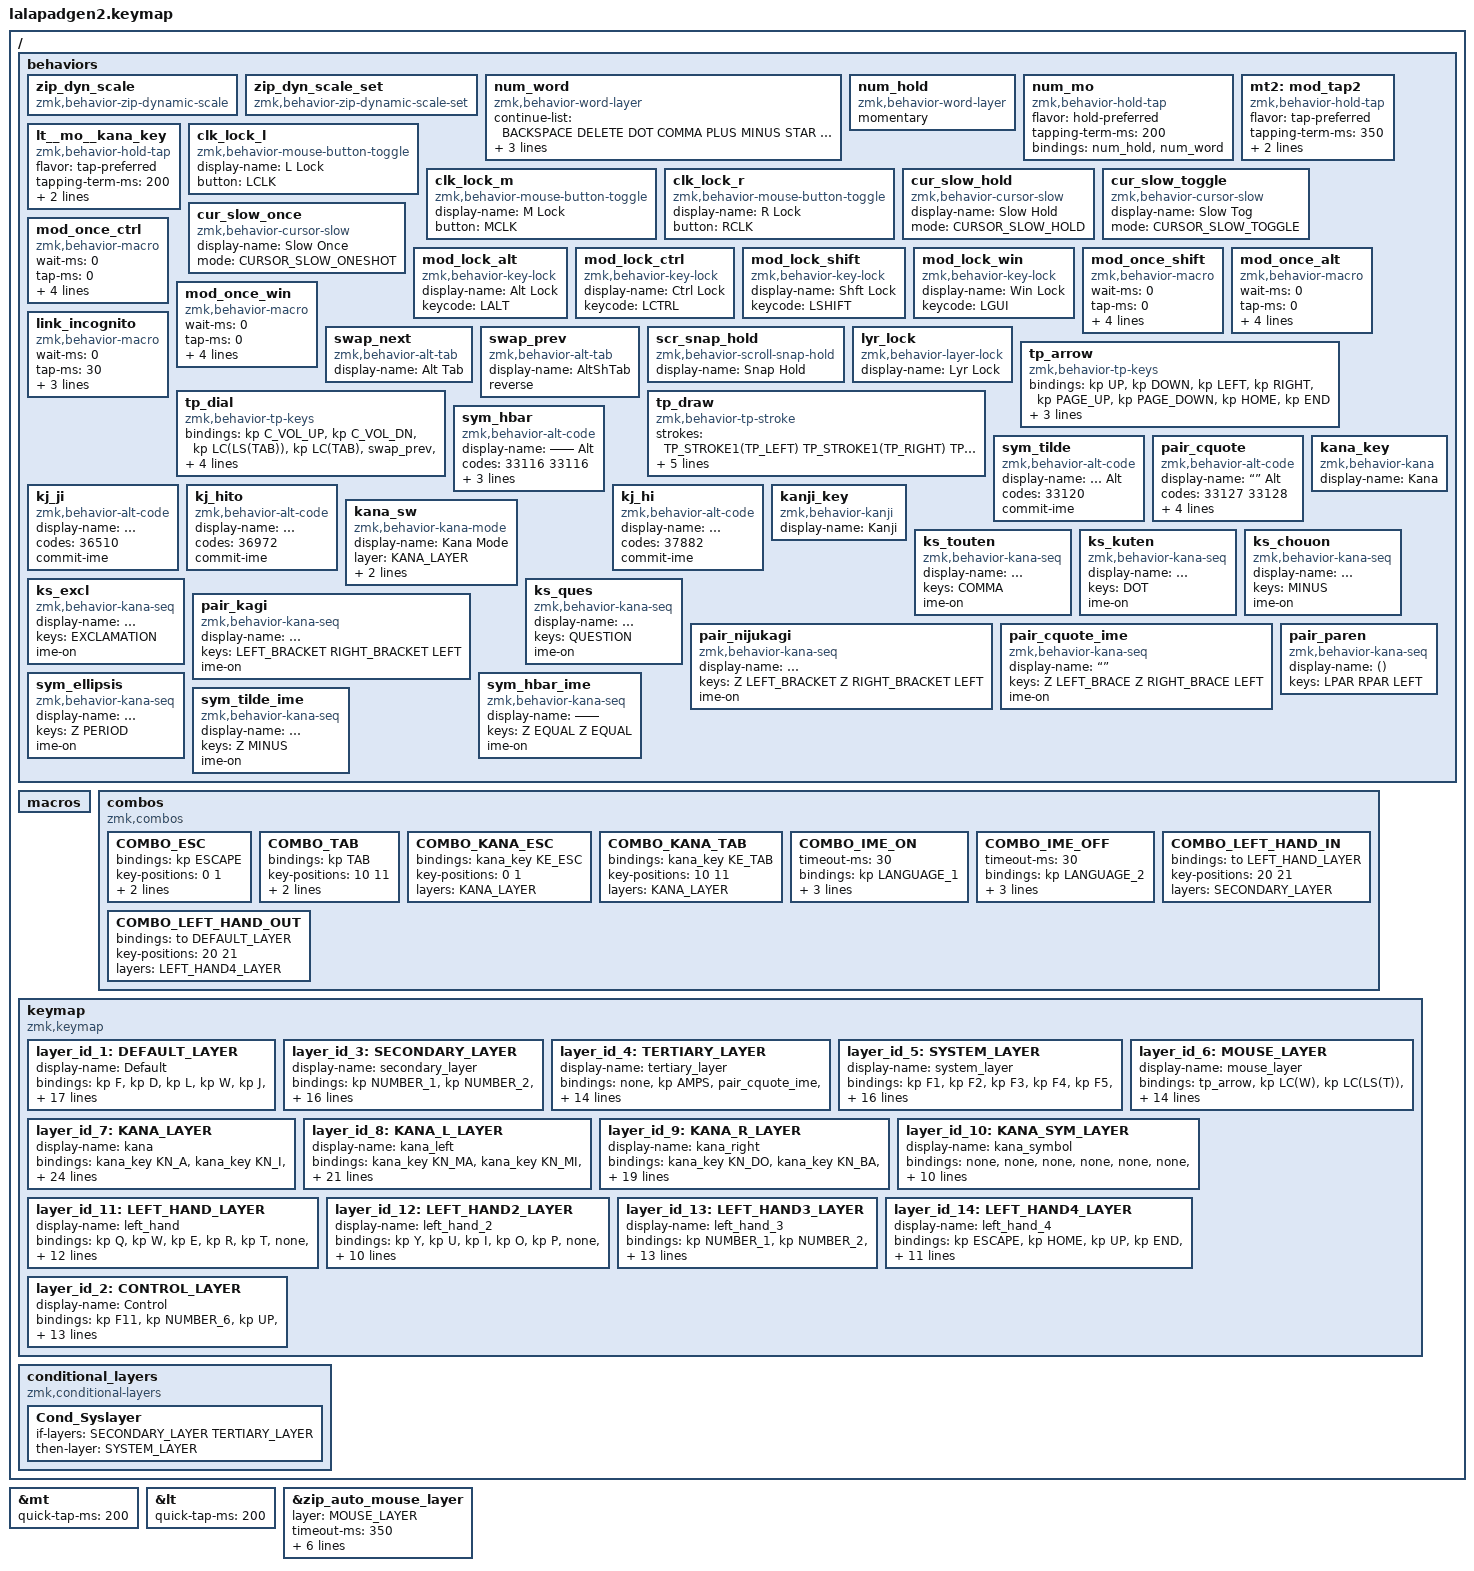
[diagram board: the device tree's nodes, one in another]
#include <input/processors.dtsi>
#include <dt-bindings/zmk/zip_dynamic_scale.h>
#include <behaviors.dtsi>
#include <dt-bindings/zmk/bt.h>
#include <dt-bindings/zmk/keys.h>
#include <dt-bindings/zmk/outputs.h>
#include <dt-bindings/zmk/pointing.h>
#include <behaviors/kana.dtsi>
#include <dt-bindings/kana/kanji.h>
#include <behaviors/mouse_button_toggle.dtsi>
#include <dt-bindings/lalapad/cursor_slow.h>
#include <dt-bindings/lalapad/tp_keys.h>
#include <dt-bindings/lalapad/tp_positions.h>

#define DEFAULT_LAYER   0
#define CONTROL_LAYER   13
#define SECONDARY_LAYER 1
#define TERTIARY_LAYER  2
#define SYSTEM_LAYER    3
#define MOUSE_LAYER     4
#define KANA_LAYER      5
#define KANA_L_LAYER    6
#define KANA_R_LAYER    7
#define KANA_SYM_LAYER  8
#define LEFT_HAND_LAYER  9
#define LEFT_HAND2_LAYER 10
#define LEFT_HAND3_LAYER 11
#define LEFT_HAND4_LAYER 12

// &mt・&lt: 短く押してから 200ms 以内にもう一度押し続けると、長押しにせずタップを押し続ける（Space の連続入力など）。
// &mt は今どこにも置いていない（エディタで置いたときの既定）
&mt { quick-tap-ms = <200>; };

&lt { quick-tap-ms = <200>; };

// オートマウスレイヤー（lalapadgen2.dtsi）のうち、マウスレイヤーに結びつく設定
// - layer: トラックパッドを操作したときに有効にするレイヤー。timeout-ms: 指とキーを離してから解除するまでの時間
// - excluded-layers: 数字・記号レイヤーの間は、トラックパッドを操作してもマウスレイヤーにしない
// - excluded-positions: マウスレイヤーで &trans でも、押しても解除せず、押している間は時間切れにしない位置
//   （トラックパッドのクリック・ジェスチャー 52〜67。POS_TP_* は dt-bindings/lalapad/tp_positions.h。離してから数え直す）
// - passive-positions: マウスレイヤーに割り当てがあっても、押しても解除も延長もしない位置（親指の段の 30〜41 のうち、
//   33・34 以外。マウスレイヤーで &trans の位置（36〜38）は、ほかのキーと同じく押すと解除する）
&zip_auto_mouse_layer {
    layer = <MOUSE_LAYER>;
    timeout-ms = <350>;
    excluded-layers = <SECONDARY_LAYER TERTIARY_LAYER>;
    excluded-positions = <
        POS_TP_LCLK_L POS_TP_RCLK_L POS_TP_MCLK_L POS_TP_LCLK_R POS_TP_RCLK_R POS_TP_MCLK_R
        POS_TP_SWIPE_RIGHT_L POS_TP_SWIPE_LEFT_L POS_TP_SWIPE_UP_L POS_TP_SWIPE_DOWN_L POS_TP_PINCH_L
        POS_TP_SWIPE_RIGHT_R POS_TP_SWIPE_LEFT_R POS_TP_SWIPE_UP_R POS_TP_SWIPE_DOWN_R POS_TP_PINCH_R
    >;
    passive-positions = <30 31 32 35 36 37 38 39 40 41>;
};


/ {
    behaviors {
        zip_dyn_scale: zip_dyn_scale {
            compatible = "zmk,behavior-zip-dynamic-scale";
            #binding-cells = <2>;
        };

        zip_dyn_scale_set: zip_dyn_scale_set {
            compatible = "zmk,behavior-zip-dynamic-scale-set";
            #binding-cells = <2>;
        };

        // Num Word（自作モジュール lalapad/ の zmk,behavior-word-layer）: 数字レイヤーを、数字と continue-list のキー
        // （Backspace・Delete・. , + - * / =）を押している間だけ続け、ほかのキーを押すと自動で戻す。Shift などの修飾キーでは
        // 戻さない（ignore-modifiers）。ほかの操作（20＋21 のコンボの &to など）で数字レイヤーが解除されたら、こちらも終わる。
        // 記号レイヤー（38）を押したら終える（exit-layers）: 数字レイヤーと記号レイヤーが同時に有効になると
        // システムレイヤー（bootloader・BT_CLR など）になるため。Num Word の間に 38 を押すと、記号レイヤーになる。
        // 使い方: &num_word SECONDARY_LAYER
        num_word: num_word {
            compatible = "zmk,behavior-word-layer";
            #binding-cells = <1>;
            continue-list = <BACKSPACE DELETE DOT COMMA PLUS MINUS STAR FSLH EQUAL>;
            ignore-numbers;
            ignore-modifiers;
            exit-layers = <TERTIARY_LAYER>;
        };

        // 33 の長押し: 押している間だけ数字レイヤー（&mo と同じ）。Num Word の間に押したら、Num Word を引き継ぐ
        // （ほかのキーや 38 を押しても数字レイヤーのまま。33 と 38 でシステムレイヤーになる）。
        // 使い方: &num_hold SECONDARY_LAYER
        num_hold: num_hold {
            compatible = "zmk,behavior-word-layer";
            #binding-cells = <1>;
            momentary;
        };

        // 33: タップで Num Word（数字レイヤーを、数字を打っている間だけ続ける）、長押しで今までどおり押している間だけ
        // 数字レイヤー（num_hold）。長押しの間にほかのキーを押したら、すぐに長押しとして扱う（hold-preferred）。
        // 使い方: &num_mo SECONDARY_LAYER SECONDARY_LAYER
        num_mo: num_mo {
            compatible = "zmk,behavior-hold-tap";
            #binding-cells = <2>;
            flavor = "hold-preferred";
            tapping-term-ms = <200>;
            bindings = <&num_hold>, <&num_word>;
        };

        mt2: mod_tap2 {
            compatible = "zmk,behavior-hold-tap";
            #binding-cells = <2>;
            flavor = "tap-preferred";
            tapping-term-ms = <350>;
            quick-tap-ms = <200>;
            // require-prior-idle-ms（以前は 125）は外した。直前の打鍵から 125ms 以内に押すと、長押ししても
            // Shift にならず、押したままのタップとして rrrr と連続入力になったため。戻すときは次の行を足す
            //   require-prior-idle-ms = <125>;
            bindings = <&kp>, <&kp>;
        };
        lt__mo__kana_key: lt__mo__kana_key {
            compatible = "zmk,behavior-hold-tap";
            #binding-cells = <2>;
            flavor = "tap-preferred";
            tapping-term-ms = <200>;
            quick-tap-ms = <200>;
            bindings = <&mo>, <&kana_key>;
        };

        // ===== カスタムキー（エディタで使いたいレイヤーに割り当てる） =====
        // 名前の頭で種類を分けている（clk_: クリック、cur_: カーソル、mod_: 修飾キー、swap_: ウィンドウの切り替え、scr_: スクロール、lyr_: レイヤー、num_: Num Word、link_: Chrome のリンク、tp_: トラックパッドでキー操作、ks_: かなと一緒に打つ記号、pair_: カッコ、sym_: 記号、kj_: 漢字 1 文字、kana_: かな）。
        // display-name は ZMK Studio の一覧とキーの上に出る名前（キーの上は 9 文字まで）。

        // --- clk_: クリック押しっぱなし（もう一度押す、または同じボタンのクリックで解除） ---
        // 左クリック押しっぱなし（旧 D.LCK）
        clk_lock_l: clk_lock_l {
            compatible = "zmk,behavior-mouse-button-toggle";
            display-name = "L Lock";
            #binding-cells = <0>;
            button = <LCLK>;
        };
        // 中クリック押しっぱなし（旧 D.MID）
        clk_lock_m: clk_lock_m {
            compatible = "zmk,behavior-mouse-button-toggle";
            display-name = "M Lock";
            #binding-cells = <0>;
            button = <MCLK>;
        };
        // 右クリック押しっぱなし（旧 D.RCK）
        clk_lock_r: clk_lock_r {
            compatible = "zmk,behavior-mouse-button-toggle";
            display-name = "R Lock";
            #binding-cells = <0>;
            button = <RCLK>;
        };

        // --- cur_: カーソル低速（1/3） ---
        // 押している間、カーソル低速（旧 SLOW）
        cur_slow_hold: cur_slow_hold {
            compatible = "zmk,behavior-cursor-slow";
            display-name = "Slow Hold";
            #binding-cells = <0>;
            mode = <CURSOR_SLOW_HOLD>;
        };
        // 押すたびにカーソル低速のオン・オフ（旧 T.SLO）
        cur_slow_toggle: cur_slow_toggle {
            compatible = "zmk,behavior-cursor-slow";
            display-name = "Slow Tog";
            #binding-cells = <0>;
            mode = <CURSOR_SLOW_TOGGLE>;
        };
        // 次のキーを押すまでカーソル低速（旧 O.SLO）
        cur_slow_once: cur_slow_once {
            compatible = "zmk,behavior-cursor-slow";
            display-name = "Slow Once";
            #binding-cells = <0>;
            mode = <CURSOR_SLOW_ONESHOT>;
        };

        // --- mod_: 修飾キー押しっぱなし（もう一度押すと解除） ---
        // Left Alt 押しっぱなし（旧 A.LCK）
        mod_lock_alt: mod_lock_alt {
            compatible = "zmk,behavior-key-lock";
            display-name = "Alt Lock";
            #binding-cells = <0>;
            keycode = <LALT>;
        };
        // Left Ctrl 押しっぱなし（旧 C.LCK）
        mod_lock_ctrl: mod_lock_ctrl {
            compatible = "zmk,behavior-key-lock";
            display-name = "Ctrl Lock";
            #binding-cells = <0>;
            keycode = <LCTRL>;
        };
        // Left Shift 押しっぱなし（旧 S.LCK）
        mod_lock_shift: mod_lock_shift {
            compatible = "zmk,behavior-key-lock";
            display-name = "Shft Lock";
            #binding-cells = <0>;
            keycode = <LSHIFT>;
        };
        // Left GUI（Win）押しっぱなし（旧 W.LCK）
        mod_lock_win: mod_lock_win {
            compatible = "zmk,behavior-key-lock";
            display-name = "Win Lock";
            #binding-cells = <0>;
            keycode = <LGUI>;
        };

        // --- mod_: 修飾キーを次の1キーだけにかける（ZMK 標準の &sk。押してから離し、次のキーを押すとそのキーと一緒に送られる。
        // 押したまま別のキーを押せば、ふつうの修飾キーとして働く） ---
        // &sk は引数でキーを受け取るので、名前付きのキーにするためマクロで包む（押したとき &sk を押し、離したとき離す）。
        // Left Ctrl を次の1キーだけ
        mod_once_ctrl: mod_once_ctrl {
            compatible = "zmk,behavior-macro";
            #binding-cells = <0>;
            wait-ms = <0>;
            tap-ms = <0>;
            bindings
                = <&macro_press &sk LCTRL>
                , <&macro_pause_for_release>
                , <&macro_release &sk LCTRL>
                ;
            display-name = "Ctrl Once";
        };
        // Left Shift を次の1キーだけ
        mod_once_shift: mod_once_shift {
            compatible = "zmk,behavior-macro";
            #binding-cells = <0>;
            wait-ms = <0>;
            tap-ms = <0>;
            bindings
                = <&macro_press &sk LSHIFT>
                , <&macro_pause_for_release>
                , <&macro_release &sk LSHIFT>
                ;
            display-name = "Shft Once";
        };
        // Left Alt を次の1キーだけ
        mod_once_alt: mod_once_alt {
            compatible = "zmk,behavior-macro";
            #binding-cells = <0>;
            wait-ms = <0>;
            tap-ms = <0>;
            bindings
                = <&macro_press &sk LALT>
                , <&macro_pause_for_release>
                , <&macro_release &sk LALT>
                ;
            display-name = "Alt Once";
        };
        // Left GUI（Win）を次の1キーだけ
        mod_once_win: mod_once_win {
            compatible = "zmk,behavior-macro";
            #binding-cells = <0>;
            wait-ms = <0>;
            tap-ms = <0>;
            bindings
                = <&macro_press &sk LGUI>
                , <&macro_pause_for_release>
                , <&macro_release &sk LGUI>
                ;
            display-name = "Win Once";
        };

        // --- swap_: ウィンドウの切り替え（Alt+Tab。自作モジュール lalapad/ の zmk,behavior-alt-tab） ---
        // 最初に押したときに Alt を押したままにして、押すたびに Tab（swap_prev は Shift+Tab）を送る。
        // 押し始めたときのレイヤーを離す（&mo のキーを離す）か、ほかのキー（キーコードを送るもの。クリックやレイヤーのキーは除く）を押すと
        // Alt を離して、選んだウィンドウに切り替わる。
        // swap_next と swap_prev は Alt を共有するので、どちらから押し始めても、途中で入れ替えてもよい
        swap_next: swap_next {
            compatible = "zmk,behavior-alt-tab";
            display-name = "Alt Tab";
            #binding-cells = <0>;
        };
        swap_prev: swap_prev {
            compatible = "zmk,behavior-alt-tab";
            display-name = "AltShTab";
            #binding-cells = <0>;
            reverse;
        };

        // --- scr_: スクロール ---
        // 押している間だけ、トラックパッドの2本指スクロールを縦か横のどちらかにそろえる（スクロールスナップ）。
        // レイヤーは使わない。実際の処理は lalapadgen2.dtsi の &zip_scroll_snap_gate_R / _L
        scr_snap_hold: scr_snap_hold {
            compatible = "zmk,behavior-scroll-snap-hold";
            display-name = "Snap Hold";
            #binding-cells = <0>;
        };

        // --- lyr_: レイヤー ---
        // レイヤーを固定する（Layer Lock。自作モジュール lalapad/ の zmk,behavior-layer-lock）。押すと、このキーを置いたレイヤーを
        // 固定する（&mo のキーを離しても、オートマウスレイヤーの時間切れでも切れない。マウスレイヤーでは、&trans のキーを
        // 押しても切れず、そのキーは下のレイヤーのキーとして入力される）。もう一度押すと固定をやめて、そのレイヤーを解除する
        // （オートマウスレイヤーなら、ふだんどおり手を離してから時間を数え直す）。Default と system_layer（数字＋記号で
        // 有効になるレイヤー）以外のどのレイヤーにも置ける。かなのレイヤーの固定は、かなモードを抜けるとやめる
        lyr_lock: lyr_lock {
            compatible = "zmk,behavior-layer-lock";
            display-name = "Lyr Lock";
            #binding-cells = <0>;
        };

        // --- link_: Chrome のリンク ---
        // カーソルを合わせたリンクを、シークレットウィンドウで開く。右クリックでメニューを出し、
        // メニューの「シークレット ウィンドウでリンクを開く」のアクセスキー G を押す（メニューが出るのを 200ms 待つ）
        link_incognito: link_incognito {
            compatible = "zmk,behavior-macro";
            #binding-cells = <0>;
            wait-ms = <0>;
            tap-ms = <30>;
            bindings
                = <&macro_wait_time 200>
                , <&mkp RCLK>
                , <&macro_wait_time 0>
                , <&kp G>
                ;
            display-name = "Incognito";
        };

        // --- tp_: トラックパッドをキー操作に変える（自作モジュール lalapad/ の zmk,behavior-tp-keys・zmk,behavior-tp-stroke） ---
        // 押している間だけ、トラックパッドの動きを、カーソル・スクロールの代わりにキーの入力に変える
        // （押している間のタップ・ジェスチャーは捨てる）。実際の処理は lalapadgen2.dtsi のリスナーに入れた &zip_tp_keys。
        // 直下の bindings はどのレイヤーでも使う既定。レイヤーごとに変えるときは、子ノード（表）に layers（使うレイヤー）と
        // bindings を書き足す（このキーを押したときに有効なレイヤーを上から見て、表のあるレイヤーの表を使う。表の &trans は
        // 下のレイヤーの表、最後に既定を見る）。左右のトラックパッドで変えるときは left-bindings・right-bindings に書く。
        // 例: num { layers = <SECONDARY_LAYER>; bindings = <...>; };
        // tp-keys の bindings は 8 つ: 1 本指を上・下・左・右へ動かしたとき、2 本指を上・下・左・右へ動かしたとき
        // （2 本指も指を動かした向き。スクロールの向きではない）。4 つとも &trans にした側は、変えずにカーソル（スクロール）のまま。
        // 動き始めの向きで縦か横かを決め、指が触れ直す・離れるか、このキーを押す・離すまで変えない。
        // *-step は 1 回送るのに必要な動きの量（トラックパッドの生の値。速度の設定には影響されない）。
        // 矢印: 1 本指で ←→↑↓、2 本指で上下が PgUp・PgDn、左右が Home・End
        tp_arrow: tp_arrow {
            compatible = "zmk,behavior-tp-keys";
            #binding-cells = <0>;
            bindings
                = <&kp UP>, <&kp DOWN>, <&kp LEFT>, <&kp RIGHT>
                , <&kp PAGE_UP>, <&kp PAGE_DOWN>, <&kp HOME>, <&kp END>
                ;
            cursor-step = <150>;
            scroll-step = <300>;
            display-name = "TP Arrow";
        };
        // ダイヤル: 1 本指で上下が音量、左右がタブ（Ctrl+Shift+Tab・Ctrl+Tab）。
        // 2 本指で上下がウィンドウの切り替え（指を上へ swap_prev・下へ swap_next。このキーを押したレイヤーが切れるか
        // （マウスレイヤーなら、キーとトラックパッドから手を離して 350ms 後）、ほかのキーを押すと、選んだウィンドウに
        // 切り替わる）、左右が仮想デスクトップ（Ctrl+Win+←・→）
        tp_dial: tp_dial {
            compatible = "zmk,behavior-tp-keys";
            #binding-cells = <0>;
            bindings
                = <&kp C_VOL_UP>, <&kp C_VOL_DN>, <&kp LC(LS(TAB))>, <&kp LC(TAB)>
                , <&swap_prev>, <&swap_next>, <&kp LC(LG(LEFT))>, <&kp LC(LG(RIGHT))>
                ;
            cursor-step = <300>;
            scroll-step = <300>;
            display-name = "TP Dial";
        };
        // 一筆書き: 押したまま 1 本指で線を描き、指（またはこのキー）を離すと、描いた向きの並びに合うものを送る。
        // strokes（向きの並び）は全レイヤー共通。bindings は strokes と同じ数・同じ順番（レイヤーごと・左右ごとの書き方は上の tp-keys と同じ）。
        // ← 戻る、→ 進む、↑ 新しいタブ、↓ 再読み込み、↓→ タブを閉じる、↓← 閉じたタブを開き直す、
        // ↑← 前のタブ、↑→ 次のタブ、→↓ シークレットウィンドウ
        tp_draw: tp_draw {
            compatible = "zmk,behavior-tp-stroke";
            #binding-cells = <0>;
            strokes = <
                TP_STROKE1(TP_LEFT)
                TP_STROKE1(TP_RIGHT)
                TP_STROKE1(TP_UP)
                TP_STROKE1(TP_DOWN)
                TP_STROKE2(TP_DOWN, TP_RIGHT)
                TP_STROKE2(TP_DOWN, TP_LEFT)
                TP_STROKE2(TP_UP, TP_LEFT)
                TP_STROKE2(TP_UP, TP_RIGHT)
                TP_STROKE2(TP_RIGHT, TP_DOWN)
                >;
            bindings
                = <&kp LA(LEFT)>
                , <&kp LA(RIGHT)>
                , <&kp LC(T)>
                , <&kp F5>
                , <&kp LC(W)>
                , <&kp LC(LS(T))>
                , <&kp LC(LS(TAB))>
                , <&kp LC(TAB)>
                , <&kp LC(LS(N))>
                ;
            stroke-step = <300>;
            display-name = "TP Draw";
        };

        // --- sym_: 記号（Windows の Alt コードで送るもの。IME の状態やローマ字テーブルに関係なく入る） ---
        // ふだんは下のほうにあるローマ字テーブル版（sym_hbar_ime など）を使う。こちらは、ローマ字テーブルに
        // 登録していない PC で使うための予備（どのレイヤーにも置いていない）。
        // commit-ime: 先に IME オフで確定前の文字を確定させ、送り終えたら IME オンに戻す
        // （付けないと、確定前の文字があるときに、続きが記号の前に入ってしまう）
        // ―― （ホリゾンタルバー2つ。ダッシュ）を入力。日本語 Windows（cp932）の Alt+33116（Shift_JIS 0x815C）を2回送る。
        // Num Lock がオフなら一時的にオンにして、送り終えたら元に戻す（CONFIG_ZMK_HID_INDICATORS）
        sym_hbar: sym_hbar {
            compatible = "zmk,behavior-alt-code";
            display-name = "―― Alt";
            #binding-cells = <0>;
            codes = <33116 33116>;
            commit-ime;
            // 送る操作（押す・離す）が多い（最大 32）ので、pair_cquote と同じく間隔を広げる
            tap-ms = <10>;
            wait-ms = <10>;
        };
        // ～ （全角チルダ U+FF5E）を入力。日本語 Windows（cp932）の Alt+33120（Shift_JIS 0x8160）で送る。
        sym_tilde: sym_tilde {
            compatible = "zmk,behavior-alt-code";
            display-name = "～ Alt";
            #binding-cells = <0>;
            codes = <33120>;
            commit-ime;
        };
        // “” を入力してカーソルを中に。Alt+33127 = “、Alt+33128 = ”（Shift_JIS 0x8167・0x8168）
        pair_cquote: pair_cquote {
            compatible = "zmk,behavior-alt-code";
            display-name = "“” Alt";
            #binding-cells = <0>;
            codes = <33127 33128>;
            cursor-left = <1>;
            commit-ime;
            // 送る操作（押す・離す）が多い（最大 34）ので、Bluetooth の送信待ちがあふれないよう間隔を広げる
            tap-ms = <10>;
            wait-ms = <10>;
        };

        // --- kj_: 漢字 1 文字（ミニ漢直。Windows の Alt コードで送る。ローマ字テーブルに関係なく、確定した文字で入る） ---
        // 押すと Num Word を終える（「3時」のように打ったら、元のレイヤーに戻る）。数字レイヤーの 20〜22 に置いている
        // （20＋21 は左手用レイヤーに入る同時押しでもあるので、日・人 は同時押しの判定の分だけ遅れて入り、ほぼ同時に押すと入らない）。
        // commit-ime: IME オンで打った確定前の数字（「3」）を先に確定させる（付けないと「時3」の順に入る）。
        // 送り終えると IME オンになる（IME オフのときに押した場合も）
        // 時（Shift_JIS 0x8E9E）
        kj_ji: kj_ji {
            compatible = "zmk,behavior-alt-code";
            display-name = "時";
            #binding-cells = <0>;
            codes = <36510>;
            commit-ime;
        };
        // 人（Shift_JIS 0x906C）
        kj_hito: kj_hito {
            compatible = "zmk,behavior-alt-code";
            display-name = "人";
            #binding-cells = <0>;
            codes = <36972>;
            commit-ime;
        };
        // 日（Shift_JIS 0x93FA）
        kj_hi: kj_hi {
            compatible = "zmk,behavior-alt-code";
            display-name = "日";
            #binding-cells = <0>;
            codes = <37882>;
            commit-ime;
        };

        // --- かな入力（自作モジュール lalapad/）。Keymap Editor が認識できるよう、定義はこのファイルに置く ---
        // かな・編集用のキーを送る（&kana_key KN_A など。ID は lalapad/include/dt-bindings/kana/kana.h。
        // KN_ = かな、KE_ = スペース・エンター・バックスペース・Esc・Tab）。記号は、下の zmk,behavior-kana-seq のキーで送る
        kana_key: kana_key {
            compatible = "zmk,behavior-kana";
            #binding-cells = <1>;
            display-name = "Kana";
        };
        // 漢字を送る（&kanji_key KJ_… など。名前と番号は lalapad/include/dt-bindings/kana/kanji.h。
        // docs/google-ime/kanji.tsv から docs/tools/gen_kanji.py で作る）。番号の符号（「;」＋英字 2 文字）を
        // かなと同じ送信キューで送り、PC 側の Google 日本語入力のローマ字テーブルが漢字に変える。かなモードの間だけ働く。
        // kanji.tsv の「同時押し」に書いたかなのキーを同時に押しても漢字が出る（同時とみなす時間は chord-ms。既定 40 ms）
        kanji_key: kanji_key {
            compatible = "zmk,behavior-kanji";
            #binding-cells = <1>;
            display-name = "Kanji";
        };
        // かな配列モードのオン／オフ（&kana_sw KANA_SW_ON / KANA_SW_OFF）。layer はかな単打面。
        // sub-layers は、かなモードを抜けるときにいっしょに解除するレイヤー（親指を押したまま抜けても残らないように）
        kana_sw: kana_sw {
            compatible = "zmk,behavior-kana-mode";
            #binding-cells = <1>;
            display-name = "Kana Mode";
            layer = <KANA_LAYER>;
            sub-layers = <KANA_L_LAYER KANA_R_LAYER KANA_SYM_LAYER>;
        };

        // --- 記号・カッコ（自作モジュール lalapad/ の zmk,behavior-kana-seq。keys に書いた打鍵を順に送る） ---
        // かな（&kana_key）と同じ送信待ちの列に並ぶので、かなのレイヤーにも、ほかのレイヤーにも置ける。
        // かなモードを抜ける処理の最中に押したときは捨て、送信待ちがあふれたときは順番を守って打ち切る
        // （ZMK 標準のマクロには、この処理がない）。新しい記号は、ここに同じ形で書き足すだけでよい。
        // ime-on: かなモードでないとき、打鍵の前に毎回 IME オン（LANGUAGE_1）を送る（入力後も IME はオンのまま）。
        // かなモード中は、ime-on の有無に関係なく、しばらく打っていなかったとき（と、接続先の切り替えやトラックパッドの
        // クリック・ジェスチャーの後）だけ IME オンを先に送る。

        // --- ks_: かなと一緒に打つ記号 ---
        ks_touten: ks_touten {
            compatible = "zmk,behavior-kana-seq";
            display-name = "、";
            #binding-cells = <0>;
            keys = <COMMA>;
            ime-on;
        };
        ks_kuten: ks_kuten {
            compatible = "zmk,behavior-kana-seq";
            display-name = "。";
            #binding-cells = <0>;
            keys = <DOT>;
            ime-on;
        };
        ks_chouon: ks_chouon {
            compatible = "zmk,behavior-kana-seq";
            display-name = "ー";
            #binding-cells = <0>;
            keys = <MINUS>;
            ime-on;
        };
        ks_excl: ks_excl {
            compatible = "zmk,behavior-kana-seq";
            display-name = "！";
            #binding-cells = <0>;
            keys = <EXCLAMATION>;
            ime-on;
        };
        ks_ques: ks_ques {
            compatible = "zmk,behavior-kana-seq";
            display-name = "？";
            #binding-cells = <0>;
            keys = <QUESTION>;
            ime-on;
        };

        // --- pair_: カッコの自動補完（開き・閉じを入力して ← でカーソルを中に置く） ---
        // 「」を入力してカーソルを中に。[ ] を Google 日本語入力で「」にする
        pair_kagi: pair_kagi {
            compatible = "zmk,behavior-kana-seq";
            display-name = "「」";
            #binding-cells = <0>;
            keys = <LEFT_BRACKET RIGHT_BRACKET LEFT>;
            ime-on;
        };
        // 『』を入力してカーソルを中に。Google 日本語入力の z[ z] で『』にする
        pair_nijukagi: pair_nijukagi {
            compatible = "zmk,behavior-kana-seq";
            display-name = "『』";
            #binding-cells = <0>;
            keys = <Z LEFT_BRACKET Z RIGHT_BRACKET LEFT>;
            ime-on;
        };
        // “” を入力してカーソルを中に。ローマ字テーブルの z{ z} で “ ” にする。
        // PC 側でローマ字テーブルに「z{ → “」「z} → ”」の登録が必要（標準のテーブルにはない）
        pair_cquote_ime: pair_cquote_ime {
            compatible = "zmk,behavior-kana-seq";
            display-name = "“”";
            #binding-cells = <0>;
            keys = <Z LEFT_BRACE Z RIGHT_BRACE LEFT>;
            ime-on;
        };
        // () を入力してカーソルを中に（かなモード以外では IME を切り替えない。IME オンなら（）になる）
        pair_paren: pair_paren {
            compatible = "zmk,behavior-kana-seq";
            display-name = "()";
            #binding-cells = <0>;
            keys = <LPAR RPAR LEFT>;
        };

        // --- sym_: 記号（Google 日本語入力のローマ字テーブル経由） ---
        // … を入力。Google 日本語入力の z. で … にする
        sym_ellipsis: sym_ellipsis {
            compatible = "zmk,behavior-kana-seq";
            display-name = "…";
            #binding-cells = <0>;
            keys = <Z PERIOD>;
            ime-on;
        };
        // ―― （ホリゾンタルバー2つ。ダッシュ）を入力。ローマ字テーブルの z= で ― にするのを2回送る。
        // PC 側でローマ字テーブルに「z= → ―」の登録が必要（標準のテーブルにはない）
        sym_hbar_ime: sym_hbar_ime {
            compatible = "zmk,behavior-kana-seq";
            display-name = "――";
            #binding-cells = <0>;
            keys = <Z EQUAL Z EQUAL>;
            ime-on;
        };
        // ～ を入力。ローマ字テーブルの z- で ～（全角チルダ）にする（標準のテーブルの z- は 〜（波ダッシュ）。
        // docs/google-ime/romantable.txt で ～ に変えている）
        sym_tilde_ime: sym_tilde_ime {
            compatible = "zmk,behavior-kana-seq";
            display-name = "～";
            #binding-cells = <0>;
            keys = <Z MINUS>;
            ime-on;
        };
    };

    // エディタ（LaLapad-Gen2-Editor）が作るマクロ用。
    macros {
    };

    combos {
        compatible = "zmk,combos";

        // Esc・Tab は、数字レイヤー（SECONDARY）では働かない（1・2、6・7 を続けて素早く打ったときに出ないように）
        COMBO_ESC {
            bindings = <&kp ESCAPE>;
            key-positions = <0 1>;
            layers = <DEFAULT_LAYER CONTROL_LAYER TERTIARY_LAYER SYSTEM_LAYER MOUSE_LAYER>;
        };
        COMBO_TAB {
            bindings = <&kp TAB>;
            key-positions = <10 11>;
            layers = <DEFAULT_LAYER CONTROL_LAYER TERTIARY_LAYER SYSTEM_LAYER MOUSE_LAYER>;
        };
        // かなの単打の面の Esc・Tab は、かなと同じ送信キューで送る（まだ送り終えていないかなを追い越さないように）
        COMBO_KANA_ESC {
            bindings = <&kana_key KE_ESC>;
            key-positions = <0 1>;
            layers = <KANA_LAYER>;
        };
        COMBO_KANA_TAB {
            bindings = <&kana_key KE_TAB>;
            key-positions = <10 11>;
            layers = <KANA_LAYER>;
        };
        // Default レイヤーだけ: 16＋17 で IME オン、12＋13 で IME オフ。打っている途中で起きないよう、30ms 以内に
        // 両方を押したときだけ（timeout-ms）、直前のキーから 150ms 以上あけて押したときだけ（require-prior-idle-ms）
        COMBO_IME_ON {
            timeout-ms = <30>;
            bindings = <&kp LANGUAGE_1>;
            key-positions = <16 17>;
            layers = <DEFAULT_LAYER>;
            require-prior-idle-ms = <150>;
        };
        COMBO_IME_OFF {
            timeout-ms = <30>;
            bindings = <&kp LANGUAGE_2>;
            key-positions = <12 13>;
            layers = <DEFAULT_LAYER>;
            require-prior-idle-ms = <150>;
        };
        // 左手用レイヤー（10）へ: 数字レイヤーの 20＋21 だけ。Default に戻るのは left_hand_4（left_hand で 33 を長押し）の
        // 20＋21 だけ（ほかの左手用レイヤーの 20＋21 では戻らない）
        COMBO_LEFT_HAND_IN {
            bindings = <&to LEFT_HAND_LAYER>;
            key-positions = <20 21>;
            layers = <SECONDARY_LAYER>;
        };
        COMBO_LEFT_HAND_OUT {
            bindings = <&to DEFAULT_LAYER>;
            key-positions = <20 21>;
            layers = <LEFT_HAND4_LAYER>;
        };
    };

    keymap {
        compatible = "zmk,keymap";

        // layer_id_<番号>: は、レイヤーの見分けの番号（1〜255。ほかのレイヤーと重ねない）。レイヤーを作ったときに決め、
        // 名前を変えても並べ替えても変えない（レイヤーと一緒に動かす）。全部のレイヤーに付ける（一部だけだとビルドが止まる）。ファームウェアはこの番号で、ZMK Studio で保存した変更を、
        // レイヤーを並べ替え・足し・消しした後も同じレイヤーに付け替える（lalapad/src/layer_ids.c。README の「レイヤーの見分けの番号」）

        layer_id_1: DEFAULT_LAYER {
            display-name = "Default";
            bindings = <
            &kp F  &kp D  &kp L  &kp W  &kp J  &kp SEMI  &kp B  &kp O  &kp U  &kp COMMA
            &kp S  &kp T  &kp H  &kp C  &kp Y  &kp Q  &kp N  &kp A  &kp E  &kp I
            &mt2 LEFT_SHIFT X  &kp K  &kp M  &kp G  &kp V  &kp Z  &kp P  &kp SQT  &kp SLASH  &kp PERIOD
            &kp LEFT_CONTROL  &kp LWIN  &kp LEFT_ALT  &num_mo SECONDARY_LAYER SECONDARY_LAYER  &mt2 LEFT_SHIFT R  &kp ENTER  &kp BACKSPACE  &mt2 RIGHT_CONTROL SPACE  &mo TERTIARY_LAYER  &none  &kp K_APP  &mod_once_ctrl
            &tog CONTROL_LAYER  &kp RIGHT  &kp DOWN  &kp LEFT  &kp UP  &kp UP  &kp LEFT  &kp DOWN  &kp RIGHT  &kana_sw KANA_SW_ON
            &mkp LCLK  &mkp RCLK  &mkp MCLK  &mkp LCLK  &mkp RCLK  &mkp MCLK
            &mkp MB4  &mkp MB5  &kp LG(TAB)  &kp LG(D)  &kp LEFT_CONTROL  &mkp MB4  &mkp MB5  &kp LG(TAB)  &kp LG(D)  &kp LEFT_CONTROL
            >;
        };

        layer_id_3: SECONDARY_LAYER {
            display-name = "secondary_layer";
            bindings = <
            &kp NUMBER_1  &kp NUMBER_2  &kp NUMBER_3  &kp NUMBER_4  &kp NUMBER_5  &none  &kp DELETE  &sym_tilde_ime  &kp HASH  &none
            &kp NUMBER_6  &kp NUMBER_7  &kp NUMBER_8  &kp NUMBER_9  &kp NUMBER_0  &kp DLLR  &sym_ellipsis  &pair_kagi  &pair_nijukagi  &pair_paren
            &kj_hi  &kj_hito  &kj_ji  &kp COLON  &none  &none  &kp BACKSLASH  &kp ASTRK  &kp GRAVE  &kp EQUAL
            &trans  &trans  &trans  &trans  &kp LEFT_SHIFT  &trans  &trans  &trans  &trans  &trans  &trans  &kp KP_NUMLOCK
            &trans  &trans  &trans  &trans  &trans  &trans  &trans  &trans  &trans  &trans
            &trans  &trans  &trans  &trans  &trans  &trans
            &kp LC(LG(LEFT))  &kp LC(LG(RIGHT))  &trans  &trans  &trans  &kp LC(LG(LEFT))  &kp LC(LG(RIGHT))  &trans  &trans  &trans
            >;
        };

        layer_id_4: TERTIARY_LAYER {
            display-name = "tertiary_layer";
            bindings = <
            &none  &kp AMPS  &pair_cquote_ime  &swap_prev  &swap_next  &kp PAGE_UP  &kp HOME  &kp UP  &kp END  &kp PRINTSCREEN
            &kp AT  &kp EXCL  &kp MINUS  &sym_hbar_ime  &none  &kp PAGE_DOWN  &kp LEFT  &kp DOWN  &kp RIGHT  &none
            &kp BACKSLASH  &kp PRCNT  &kp CARET  &tp_arrow  &none  &none  &none  &none  &none  &none
            &trans  &trans  &trans  &trans  &kp LEFT_SHIFT  &kp LS(ENTER)  &trans  &trans  &trans  &trans  &trans  &kp CAPS
            &trans  &trans  &trans  &trans  &trans  &trans  &trans  &trans  &trans  &trans
            &trans  &trans  &trans  &trans  &trans  &trans
            &kp LG(RIGHT)  &kp LG(LEFT)  &trans  &trans  &trans  &kp LG(RIGHT)  &kp LG(LEFT)  &trans  &trans  &trans
            >;
        };

        layer_id_5: SYSTEM_LAYER {
            display-name = "system_layer";
            bindings = <
            &kp F1  &kp F2  &kp F3  &kp F4  &kp F5  &out OUT_TOG  &bt BT_SEL 0  &bt BT_SEL 1  &bt BT_SEL 2  &bt BT_SEL 3
            &kp F6  &kp F7  &kp F8  &kp F9  &kp F10  &sys_reset  &bootloader  &bt BT_CLR  &bt BT_CLR_ALL  &none
            &kp F11  &kp F12  &kp F13  &kp F14  &kp F15  &zip_dyn_scale ZDS_XY ZDS_INC  &zip_dyn_scale ZDS_XY ZDS_DEC  &zip_dyn_scale ZDS_SC ZDS_INC  &zip_dyn_scale ZDS_SC ZDS_DEC  &zip_dyn_scale ZDS_ALL ZDS_RST
            &trans  &trans  &trans  &trans  &trans  &trans  &trans  &trans  &trans  &trans  &trans  &trans
            &trans  &trans  &trans  &trans  &trans  &trans  &trans  &trans  &trans  &trans
            &trans  &trans  &trans  &trans  &trans  &trans
            &trans  &trans  &trans  &trans  &trans  &trans  &trans  &trans  &trans  &trans
            >;
        };

        layer_id_6: MOUSE_LAYER {
            display-name = "mouse_layer";
            bindings = <
            &tp_arrow  &kp LC(W)  &kp LC(LS(T))  &kp LC(A)  &none  &kp LC(LS(TAB))  &kp LC(TAB)  &none  &none  &lyr_lock
            &none  &mkp MCLK  &mkp RCLK  &mkp LCLK  &clk_lock_l  &kp RIGHT_CONTROL  &kp RIGHT_SHIFT  &link_incognito  &tp_draw  &tp_dial
            &kp LC(Z)  &kp LC(X)  &kp LC(C)  &kp LC(V)  &none  &none  &none  &kp RIGHT_ALT  &none  &none
            &none  &none  &none  &trans  &scr_snap_hold  &cur_slow_toggle  &trans  &trans  &trans  &none  &none  &none
            &trans  &kp RS(RIGHT)  &trans  &kp LS(LEFT)  &kp LC(LS(C))  &trans  &trans  &trans  &trans  &trans
            &trans  &trans  &trans  &trans  &trans  &trans
            &trans  &trans  &trans  &trans  &trans  &trans  &trans  &trans  &trans  &trans
            >;
        };

        layer_id_7: KANA_LAYER {
            display-name = "kana";
            bindings = <
            &kana_key KN_A  &kana_key KN_I  &kana_key KN_U  &kana_key KN_E  &kana_key KN_O  &kana_key KN_KA  &kana_key KN_KI  &kana_key KN_KU  &kana_key KN_KE  &kana_key KN_KO
            &kana_key KN_SA  &kana_key KN_SI  &kana_key KN_SU  &kana_key KN_SE  &kana_key KN_SO  &kana_key KN_TA  &kana_key KN_TI  &kana_key KN_TU  &kana_key KN_TE  &kana_key KN_TO
            &kana_key KN_NA  &kana_key KN_NI  &kana_key KN_NU  &kana_key KN_NE  &kana_key KN_NO  &kana_key KN_HA  &kana_key KN_HI  &kana_key KN_HU  &kana_key KN_HE  &kana_key KN_HO
            &none  &none  &none  &kana_key KE_SPACE  &mo KANA_L_LAYER  &kana_key KE_ENTER  &lt__mo__kana_key CONTROL_LAYER KE_BSPC  &mo KANA_R_LAYER  &mo KANA_SYM_LAYER  &none  &none  &none
            &none  &trans  &trans  &trans  &trans  &trans  &trans  &trans  &trans  &kana_sw KANA_SW_OFF
            &trans  &trans  &trans  &trans  &trans  &trans
            &trans  &trans  &trans  &trans  &trans  &trans  &trans  &trans  &trans  &trans
            >;
        };

        layer_id_8: KANA_L_LAYER {
            display-name = "kana_left";
            bindings = <
            &kana_key KN_MA  &kana_key KN_MI  &kana_key KN_MU  &kana_key KN_ME  &kana_key KN_MO  &kana_key KN_YA  &kana_key KN_YU  &kana_key KN_YO  &kana_key KN_WA  &kana_key KN_WO
            &kana_key KN_RA  &kana_key KN_RI  &kana_key KN_RU  &kana_key KN_RE  &kana_key KN_RO  &kana_key KN_NN  &kana_key KN_GA  &kana_key KN_GI  &kana_key KN_GU  &kana_key KN_GE
            &kana_key KN_GO  &kana_key KN_ZA  &kana_key KN_ZI  &kana_key KN_ZU  &kana_key KN_ZE  &kana_key KN_ZO  &kana_key KN_DA  &kana_key KN_DI  &kana_key KN_DU  &kana_key KN_DE
            &trans  &trans  &trans  &trans  &trans  &trans  &trans  &trans  &trans  &trans  &trans  &trans
            &trans  &trans  &trans  &trans  &trans  &trans  &trans  &trans  &trans  &trans
            &trans  &trans  &trans  &trans  &trans  &trans
            &trans  &trans  &trans  &trans  &trans  &trans  &trans  &trans  &trans  &trans
            >;
        };

        layer_id_9: KANA_R_LAYER {
            display-name = "kana_right";
            bindings = <
            &kana_key KN_DO  &kana_key KN_BA  &kana_key KN_BI  &kana_key KN_BU  &kana_key KN_BE  &kana_key KN_BO  &kana_key KN_PA  &kana_key KN_PI  &kana_key KN_PU  &kana_key KN_PE
            &kana_key KN_PO  &kana_key KN_XYA  &kana_key KN_XYU  &kana_key KN_XYO  &kana_key KN_XA  &kana_key KN_XI  &kana_key KN_XU  &kana_key KN_XE  &kana_key KN_XO  &kana_key KN_XTU
            &kana_key KN_VU  &ks_touten  &ks_kuten  &ks_chouon  &sym_ellipsis  &ks_excl  &ks_ques  &pair_kagi  &sym_hbar_ime  &pair_paren
            &trans  &trans  &trans  &trans  &trans  &trans  &trans  &trans  &trans  &trans  &trans  &trans
            &trans  &trans  &trans  &trans  &trans  &trans  &trans  &trans  &trans  &trans
            &trans  &trans  &trans  &trans  &trans  &trans
            &trans  &trans  &trans  &trans  &trans  &trans  &trans  &trans  &trans  &trans
            >;
        };

        // かな記号面（かな単打面の位置38を押している間）。記号は後で配置する。今は文字キー（0〜29）を空にしている
        layer_id_10: KANA_SYM_LAYER {
            display-name = "kana_symbol";
            bindings = <
            &none  &none  &none  &none  &none  &none  &none  &none  &none  &none
            &none  &none  &none  &none  &none  &none  &none  &none  &none  &none
            &none  &none  &none  &none  &none  &none  &none  &none  &none  &none
            &trans  &trans  &trans  &trans  &trans  &trans  &trans  &trans  &trans  &trans  &trans  &trans
            &trans  &trans  &trans  &trans  &trans  &trans  &trans  &trans  &trans  &trans
            &trans  &trans  &trans  &trans  &trans  &trans
            &trans  &trans  &trans  &trans  &trans  &trans  &trans  &trans  &trans  &trans
            >;
        };

        layer_id_11: LEFT_HAND_LAYER {
            display-name = "left_hand";
            bindings = <
            &kp Q  &kp W  &kp E  &kp R  &kp T  &none  &none  &none  &none  &none
            &kp A  &kp S  &kp D  &kp F  &kp G  &none  &none  &none  &none  &none
            &kp Z  &kp X  &kp C  &kp V  &kp B  &none  &none  &none  &none  &none
            &kp LWIN  &kp LANGUAGE_2  &kp LANGUAGE_1  &lt LEFT_HAND4_LAYER SPACE  &mo LEFT_HAND2_LAYER  &mo LEFT_HAND3_LAYER  &none  &none  &none  &none  &none  &none
            &none  &trans  &trans  &trans  &trans  &none  &none  &none  &none  &none
            &trans  &trans  &trans  &trans  &trans  &trans
            &trans  &trans  &trans  &trans  &trans  &trans  &trans  &trans  &trans  &trans
            >;
        };

        layer_id_12: LEFT_HAND2_LAYER {
            display-name = "left_hand_2";
            bindings = <
            &kp Y  &kp U  &kp I  &kp O  &kp P  &none  &none  &none  &none  &none
            &kp H  &kp J  &kp K  &kp L  &kp MINUS  &none  &none  &none  &none  &none
            &kp N  &kp M  &kp COMMA  &kp PERIOD  &kp QMARK  &none  &none  &none  &none  &none
            &none  &none  &none  &none  &none  &none  &none  &none  &none  &none  &none  &none
            &none  &none  &none  &none  &none  &none  &none  &none  &none  &none
            &trans  &trans  &trans  &trans  &trans  &trans
            &trans  &trans  &trans  &trans  &trans  &trans  &trans  &trans  &trans  &trans
            >;
        };

        layer_id_13: LEFT_HAND3_LAYER {
            display-name = "left_hand_3";
            bindings = <
            &kp NUMBER_1  &kp NUMBER_2  &kp NUMBER_3  &kp NUMBER_4  &kp NUMBER_5  &none  &none  &none  &none  &none
            &kp NUMBER_6  &kp NUMBER_7  &kp NUMBER_8  &kp NUMBER_9  &kp NUMBER_0  &none  &none  &none  &none  &none
            &sym_hbar_ime  &mod_once_ctrl  &mod_lock_shift  &pair_cquote_ime  &pair_kagi  &none  &none  &none  &none  &none
            &none  &none  &none  &none  &none  &none  &none  &none  &none  &none  &none  &none
            &none  &none  &none  &none  &none  &none  &none  &none  &none  &none
            &trans  &trans  &trans  &trans  &trans  &trans
            &trans  &trans  &trans  &trans  &trans  &trans  &trans  &trans  &trans  &trans
            >;
        };

        layer_id_14: LEFT_HAND4_LAYER {
            display-name = "left_hand_4";
            bindings = <
            &kp ESCAPE  &kp HOME  &kp UP  &kp END  &kp PAGE_UP  &none  &none  &none  &none  &none
            &kp TAB  &kp LEFT  &kp DOWN  &kp RIGHT  &kp PAGE_DOWN  &none  &none  &none  &none  &none
            &none  &none  &link_incognito  &kp PAUSE_BREAK  &none  &none  &none  &none  &none  &none
            &none  &none  &none  &none  &none  &none  &none  &none  &none  &none  &none  &none
            &none  &none  &none  &none  &none  &none  &none  &none  &none  &none
            &trans  &trans  &trans  &trans  &trans  &trans
            &trans  &trans  &trans  &trans  &trans  &trans  &trans  &trans  &trans  &trans
            >;
        };

        // Control レイヤー（Default の 42 を押すたびに入る／戻る）。左右に、矢印・Page Up／Down・数字・F11 を置く（上の段は左右対称、矢印の段は左右とも同じ並び）。
        // Default のすぐ上に置くので、数字・記号・マウス・かなのレイヤーは、この上に重なって今までどおり使える。
        layer_id_2: CONTROL_LAYER {
            display-name = "Control";
            bindings = <
            &kp F11  &kp NUMBER_6  &kp UP  &kp NUMBER_9  &kp PAGE_UP  &kp PAGE_UP  &kp NUMBER_9  &kp UP  &kp NUMBER_6  &kp F11
            &none  &kp LEFT  &kp DOWN  &kp RIGHT  &kp PAGE_DOWN  &kp PAGE_DOWN  &kp LEFT  &kp DOWN  &kp RIGHT  &none
            &none  &none  &none  &none  &none  &none  &none  &none  &none  &none
            &trans  &trans  &trans  &trans  &trans  &trans  &trans  &trans  &trans  &trans  &trans  &trans
            &tog CONTROL_LAYER  &trans  &trans  &trans  &trans  &trans  &trans  &trans  &trans  &trans
            &trans  &trans  &trans  &trans  &trans  &trans
            &trans  &trans  &trans  &trans  &trans  &trans  &trans  &trans  &trans  &trans
            >;
        };
    };

    conditional_layers {
        compatible = "zmk,conditional-layers";

        Cond_Syslayer {
            if-layers = <SECONDARY_LAYER TERTIARY_LAYER>;
            then-layer = <SYSTEM_LAYER>;
        };
    };
};
